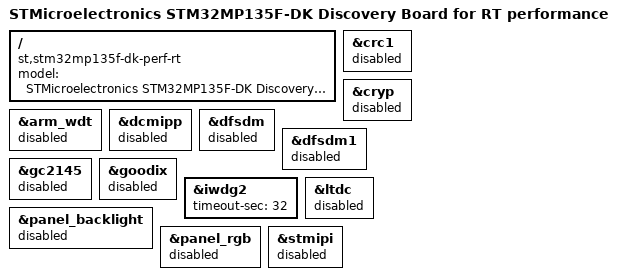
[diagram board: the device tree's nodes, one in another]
// SPDX-License-Identifier: (GPL-2.0-or-later OR BSD-3-Clause)
/*
 * Copyright (C) STMicroelectronics 2024 - All Rights Reserved
 * Author: Lionel Vitte <lionel.vitte@st.com> for STMicroelectronics.
 */

#include <stm32mp135f-dk.dts>

/ {
	model = "STMicroelectronics STM32MP135F-DK Discovery Board for RT performance";
	compatible = "st,stm32mp135f-dk-perf-rt", "st,stm32mp135f-dk-rt", "st,stm32mp135f-dk", "st,stm32mp135";
};

&arm_wdt {
	status = "disabled";
};

&crc1 {
	status = "disabled";
};

&cryp {
	status = "disabled";
};

&dcmipp {
	status = "disabled";
};

&dfsdm {
	status = "disabled";
};

&dfsdm1 {
	status = "disabled";
};

&gc2145 {
	status = "disabled";
};

&goodix {
	status = "disabled";
};

&iwdg2 {
	timeout-sec = <32>;
	status = "okay";
};

&ltdc {
	status = "disabled";
};

&panel_backlight {
	status = "disabled";
};

&panel_rgb {
	status = "disabled";
};

&stmipi {
	status = "disabled";
};
